AUTOSAR XML (schema 4-0-3)
standard types defined: UInt32, UInt8
package /AUTOSAR_Platform/DataConstrs
  range DC_UInt8: raw 0..255
package /PATAC/MSM/ComponentTypes
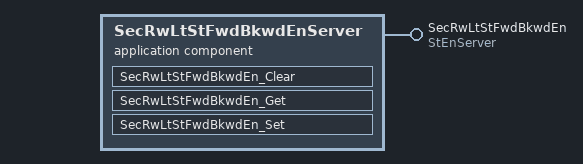
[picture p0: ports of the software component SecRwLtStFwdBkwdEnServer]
  application sw component type SecRwLtStFwdBkwdEnServer
    provide port SecRwLtStFwdBkwdEn: provided-com-specs=[{operation=Clear, queue-length=1}, {operation=Get, queue-length=1}, {operation=Set, queue-length=1}], provided-interface=StEnServer
    behavior SecRwLtStFwdBkwdEnServer_InternalBehavior
      operation invoked event OIT_SecRwLtStFwdBkwdEn_Clear_SecRwLtStFwdBkwdEn_Clear: start-on-event=SecRwLtStFwdBkwdEn_Clear, operation=SecRwLtStFwdBkwdEn.Clear
      operation invoked event OIT_SecRwLtStFwdBkwdEn_Get_SecRwLtStFwdBkwdEn_Get: start-on-event=SecRwLtStFwdBkwdEn_Get, operation=SecRwLtStFwdBkwdEn.Get
      operation invoked event OIT_SecRwLtStFwdBkwdEn_Set_SecRwLtStFwdBkwdEn_Set: start-on-event=SecRwLtStFwdBkwdEn_Set, operation=SecRwLtStFwdBkwdEn.Set
      runnable SecRwLtStFwdBkwdEn_Clear
      runnable SecRwLtStFwdBkwdEn_Get
      runnable SecRwLtStFwdBkwdEn_Set
  swc implementation SecRwLtStFwdBkwdEnServer_Implementation: behavior=SecRwLtStFwdBkwdEnServer_InternalBehavior
    code-descriptors:
      code Default: artifact-descriptors=autosar-engineering-object={short-label=Default, category=SWSRC}
package /PATAC/MSM/ModeAdjust/PortInterface
  client server interface StEnServer
    operation Clear
      arg data: type=UInt8, direction=IN, server-argument-impl-policy=USE-ARGUMENT-TYPE
    operation Get
      arg data: type=UInt32, direction=OUT, server-argument-impl-policy=USE-ARGUMENT-TYPE
    operation Set
      arg data: type=UInt8, direction=IN, server-argument-impl-policy=USE-ARGUMENT-TYPE
